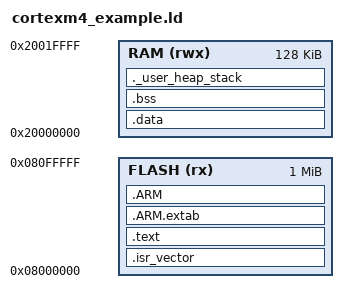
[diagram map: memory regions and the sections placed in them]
/* =============================================================================
 * Linker Script esempio Cortex-M4 (es. STM32F407VG)
 * TEMPLATE — adattare FLASH e RAM al micro effettivo.
 * =========================================================================== */
MEMORY
{
    FLASH (rx)  : ORIGIN = 0x08000000, LENGTH = 1024K
    RAM   (rwx) : ORIGIN = 0x20000000, LENGTH = 128K
}

_Min_Stack_Size = 0x4000;  /* 16 KB stack */
_Min_Heap_Size  = 0x2000;  /* 8 KB heap  */

ENTRY(Reset_Handler)

SECTIONS
{
    .isr_vector : {
        . = ALIGN(4);
        KEEP(*(.isr_vector))
        . = ALIGN(4);
    } > FLASH

    .text : {
        . = ALIGN(4);
        *(.text) *(.text*) *(.rodata) *(.rodata*)
        *(.glue_7) *(.glue_7t)
        KEEP(*(.init)) KEEP(*(.fini))
        . = ALIGN(4);
    } > FLASH

    .ARM.extab : {
        *(.ARM.extab* .gnu.linkonce.armextab.*)
    } > FLASH

    .ARM : {
        __exidx_start = .;
        *(.ARM.exidx*)
        __exidx_end = .;
        . = ALIGN(4);
        _etext = .;
    } > FLASH

    .data : AT(_etext) {
        . = ALIGN(4);
        _sdata = .;
        *(.data) *(.data*)
        . = ALIGN(4);
        _edata = .;
    } > RAM

    .bss : {
        . = ALIGN(4);
        _sbss = .;
        __bss_start__ = _sbss;
        *(.bss) *(.bss*) *(COMMON)
        . = ALIGN(4);
        _ebss = .;
        __bss_end__ = _ebss;
    } > RAM

    ._user_heap_stack : {
        . = ALIGN(8);
        PROVIDE(end = .);
        PROVIDE(_end = .);
        . = . + _Min_Heap_Size;
        . = . + _Min_Stack_Size;
        . = ALIGN(8);
    } > RAM

    _estack = ORIGIN(RAM) + LENGTH(RAM);
}
